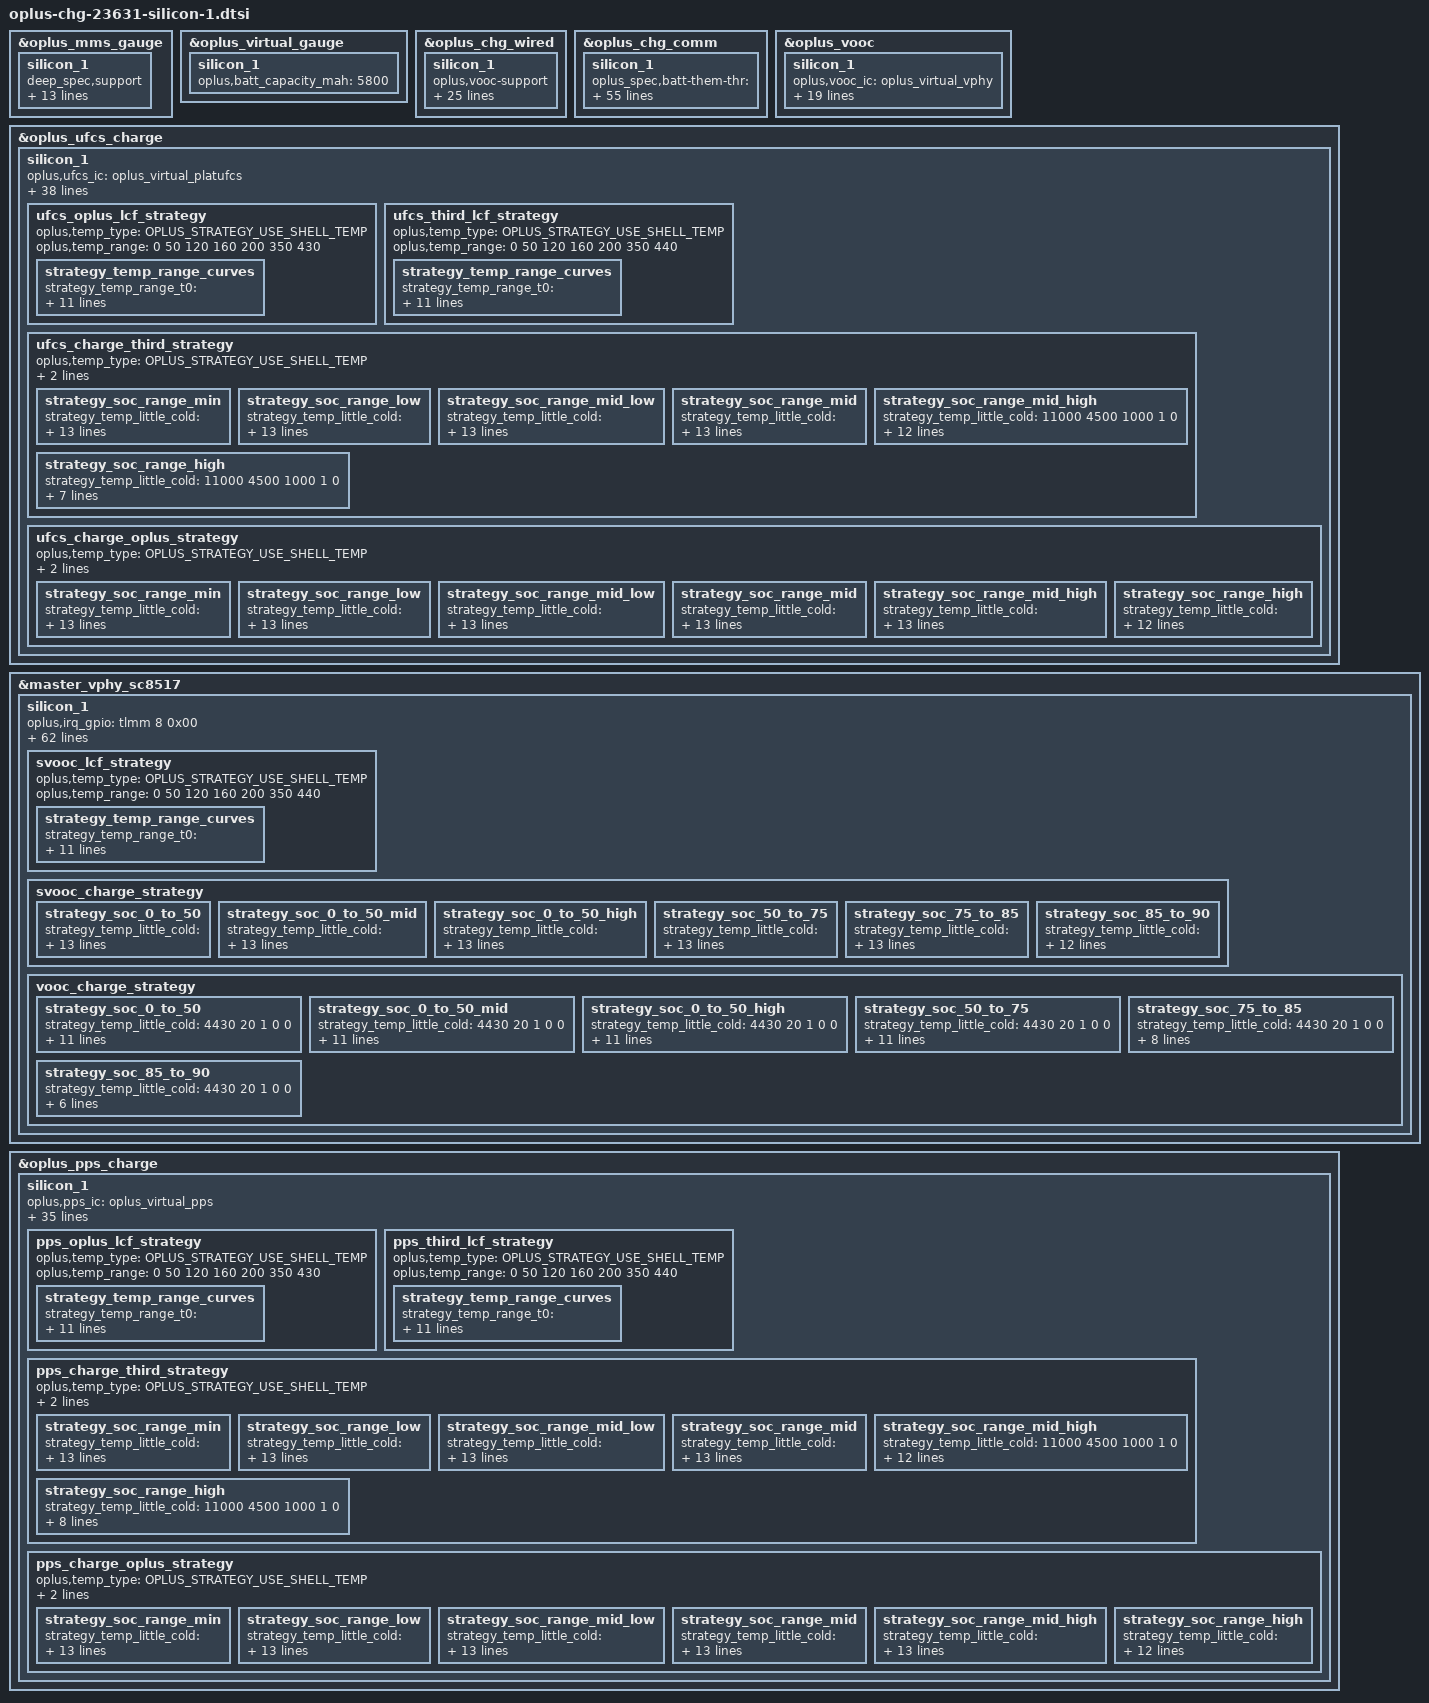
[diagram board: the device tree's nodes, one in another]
//ifdef OPLUS_FEATURE_CHG_BASIC
&oplus_mms_gauge {
	silicon_1 {
		deep_spec,support;
		deep_spec,uv_thr = <3000>;
		deep_spec,count_thr = <50>;
		deep_spec,vbat_soc = <20>;
		deep_spec,count_step = <0 1 0 400 1 1 530 2 2>;
		deep_spec,count_curve = <0 3200 3300 0
					100 3300 3370 1
					200 3350 3400 2
					300 3400 3450 3
					400 3450 3500 4>;
		deep_spec,cc_curve = 	<0 3200 3300 0
					15 3000 3150 1
					500 3100 3250 2
					1000 3200 3300 3
					1500 3200 3300 4>;
		deep_spec,batt_curve = <500 3500 5
					10000 3400 2>;
		deep_spec,cold_uv_offset = <3000 0 0
					    3100 (-100) 1
					    3200 (-200) 2
					    3300 (-300) 3
					    3350 (-300) 4
					    3400 (-300) 5
					    3450 (-300) 6>;
		deep_spec,term_coeff = <3150 238 3
					3250 380 4
					3300 428 5
					3370 570 7
					3400 665 8
					3450 665 8
					3500 665 8>;
	};
};
&oplus_virtual_gauge {
	silicon_1 {
		oplus,batt_capacity_mah = <5800>;
	};
};

&oplus_chg_wired {
	silicon_1 {
		oplus,vooc-support;

		oplus_spec,vbatt_pdqc_to_9v_thr = <5000>;
		oplus_spec,pd-iclmax-ma = <1600>;
		oplus_spec,qc-iclmax-ma = <1600>;
		oplus_spec,non-standard-ibatmax-ma = <1000>;
		oplus_spec,input-power-mw = <
			2500		/* OPLUS_WIRED_CHG_MODE_UNKNOWN */
			2500		/* OPLUS_WIRED_CHG_MODE_SDP */
			7500		/* OPLUS_WIRED_CHG_MODE_CDP */
			10000		/* OPLUS_WIRED_CHG_MODE_DCP */
			15000		/* OPLUS_WIRED_CHG_MODE_VOOC */
			14400		/* OPLUS_WIRED_CHG_MODE_QC */
			14400		/* OPLUS_WIRED_CHG_MODE_PD */
		>;
		oplus_spec,led_on-fccmax-ma = <0 1523 2538 3520 3520 3520 3520 1000 0>;
		oplus_spec,fccmax-ma-lv = <
			0 1410 2200 2200 2200 2200 2200 2200 0	/* OPLUS_WIRED_CHG_MODE_UNKNOWN */
			0 600  600  600  600  600  600  600  0	/* OPLUS_WIRED_CHG_MODE_SDP */
			0 1523 1600 1600 1600 1600 1600 1600 0	/* OPLUS_WIRED_CHG_MODE_CDP */
			0 1523 2200 2200 2200 2200 2200 2200 0	/* OPLUS_WIRED_CHG_MODE_DCP */
			0 1523 2538 3300 3300 3300 3300 3046 0	/* OPLUS_WIRED_CHG_MODE_VOOC */
			0 1523 2538 3520 3520 3520 3520 3046 0	/* OPLUS_WIRED_CHG_MODE_QC */
			0 1523 2538 3520 3520 3520 3520 3046 0	/* OPLUS_WIRED_CHG_MODE_PD */
		>;
		oplus_spec,fccmax-ma-hv = <
			0 508  846  2200 2200 2200 2200 2200 0	/* OPLUS_WIRED_CHG_MODE_UNKNOWN */
			0 508  600  600  600  600  600  600  0	/* OPLUS_WIRED_CHG_MODE_SDP */
			0 508  1015 1600 1600 1600 1600 1600 0	/* OPLUS_WIRED_CHG_MODE_CDP */
			0 508  1015 2200 2200 2200 2200 2200 0	/* OPLUS_WIRED_CHG_MODE_DCP */
			0 508  1015 2538 2538 3600 3600 3046 0	/* OPLUS_WIRED_CHG_MODE_VOOC */
			0 508  1015 2538 3520 3520 3520 3046 0	/* OPLUS_WIRED_CHG_MODE_QC */
			0 508  1015 2538 3520 3520 3520 3046 0	/* OPLUS_WIRED_CHG_MODE_PD */
		>;

		oplus_spec,cool_down_pdqc_vol_mv = <9000 9000 9000>;
		oplus_spec,cool_down_pdqc_curr_ma = <1200 1500 1600>;
		oplus_spec,cool_down_vooc_curr_ma = <1200 1500 2000 2500 3000 3000>;
		oplus_spec,cool_down_normal_curr_ma = <1200 1500 2000>;

		oplus_spec,vbus_ov_thr_mv = <11000 11000>;
		oplus_spec,vbus_uv_thr_mv = <4300 4300>;

		/* first data is strategy used temp type */
		oplus,vooc_strategy_name = "cgcl";
		oplus,vooc_strategy_data = <OPLUS_STRATEGY_USE_BATT_TEMP
					    0   350 3000 1 0
					    330 370 3000 2 0
					    350 440 2200 2 1>;
	};
};

&oplus_chg_comm {
	silicon_1 {
		oplus_spec,batt-them-thr = <(-100) 0 50 120 160 350 450 530>;
		oplus_spec,iterm-ma = <151>;
		oplus_spec,fv-mv = <4500 4500 4500 4500 4500 4500 4485 4130 4130>;
		oplus_spec,sw-fv-mv = <4450 4450 4450 4450 4450 4450 4435 4080 4080>;
		oplus_spec,hw-fv-inc-mv = <0 18 18 18 18 18 18 18 0>;
		oplus_spec,sw-over-fv-mv = <4510 4510 4510 4510 4510 4510 4495 4140 4140>;
		oplus_spec,sw-over-fv-dec-mv = <8>;
		oplus_spec,non-standard-sw-fv-mv = <3930>;
		oplus_spec,non-standard-fv-mv = <3980>;
		oplus_spec,non-standard-hw-fv-inc-mv = <18>;
		oplus_spec,non-standard-sw-over-fv-mv = <3990>;
		oplus_spec,non-standard-vbatdet-mv = <3680>;
		oplus_spec,wired-vbatdet-mv = <0 4200 4300 4400 4400 4400 4385 4030 0>;
		oplus_spec,fcc-gear-thr-mv = <4180>;
		oplus_spec,fcc-gear-shake-mv = <400 400 400 300 300 180 180 180 180>;
		oplus_spec,vbatt-ov-thr-mv = <4600>;

		oplus_spec,full_pre_ffc_judge;
		oplus_spec,full-pre-ffc-mv = <4495>;
		oplus_spec,ffc-temp-thr = <120 200 350 400>;
		oplus_spec,wired-ffc-step-max = <2>;
		oplus_spec,wired-ffc-fv-mv = <4590 4590>;

		oplus_spec,wired-ffc-fv-cutoff-mv = <4545 4515 4500
						     4515 4505 4490>;

		oplus_spec,removed_bat_decidegc = <390>;

		oplus_spec,wired-ffc-fcc-ma = <1100 1100 1100
					       700 700  700>;
		oplus_spec,wired-ffc-fcc-cutoff-ma = <400 400 400
						      200 200 200>;

		/* 2s battery */
		oplus_spec,wired-aging-ffc-version = <AGING_FFC_V1>;
		oplus_spec,wired-aging-ffc-offset-mv = <15 30
							10 20>;
		oplus_spec,wired-aging-ffc-cycle-thr = <500 1000>;

		oplus_spec,vbat_uv_thr_mv = <3000>;
		oplus_spec,vbat_charging_uv_thr_mv = <2900>;

		/*If use subboard NTC as battery temp, config it as 20, otherwise 0 */
		oplus_spec,tbatt_power_off_cali_temp = <0>;
		oplus_spec,poweroff_high_batt_temp = <720>;
		oplus_spec,poweroff_emergency_batt_temp = <770>;
		oplus,vooc_show_ui_soc_decimal;
		oplus,ui_soc_decimal_speedmin = <20>;

		deep_spec,uv_inc_tbatt = <(-50)>;

		oplus,ui_soc_2_voltage_comp_mv = <30>;
		oplus,chg_shutdown_max_mv = <3000>;

		oplus,gauge_stuck_jump_support;
		oplus,gauge_stuck_threshold = <15>;
		oplus,gauge_stuck_time = <50>;

		oplus,hidden_soc_switch;
		oplus,reserve_chg_soc = <3>;
		oplus,hidden_soc_percent = <20>;
	};
};

&oplus_vooc {
	silicon_1 {
		oplus,vooc_ic = <&oplus_virtual_vphy>;

		oplus_spec,vooc_soc_range = <50 75 85>;

		oplus,vooc_data_width = <7>;
		oplus,vooc_curr_max = <CURR_LIMIT_7BIT_11_5A>;
		oplus,support_vooc_by_normal_charger_path;
		oplus,vooc_project = <14>;  /* 120W, 11V10.9A */
		oplus,vooc_curr_table_type = <VOOC_CURR_TABLE_2_0>;
		oplus,vooc_power_max_w = <120>;
		oplus,voocphy_support = <2>;
		oplus,support_fake_vooc_check;
		oplus,subboard_ntc_abnormal_current = <7300>;
		oplus,smart_chg_bcc_support;
		oplus,abnormal_over_80w_adapter_current = <CURR_LIMIT_7BIT_11_5A CURR_LIMIT_7BIT_11_5A
						CURR_LIMIT_7BIT_7_0A CURR_LIMIT_7BIT_7_0A
						CURR_LIMIT_7BIT_6_0A CURR_LIMIT_7BIT_6_0A
						CURR_LIMIT_7BIT_5_0A CURR_LIMIT_7BIT_5_0A
						CURR_LIMIT_7BIT_4_0A CURR_LIMIT_7BIT_4_0A
						CURR_LIMIT_7BIT_3_0A CURR_LIMIT_7BIT_3_0A
						CURR_LIMIT_7BIT_2_0A CURR_LIMIT_7BIT_2_0A>;


		oplus,abnormal_adapter_current = <CURR_LIMIT_7BIT_11_5A CURR_LIMIT_7BIT_11_5A
						CURR_LIMIT_7BIT_5_0A CURR_LIMIT_7BIT_5_0A
						CURR_LIMIT_7BIT_4_0A CURR_LIMIT_7BIT_4_0A
						CURR_LIMIT_7BIT_3_0A CURR_LIMIT_7BIT_3_0A
						CURR_LIMIT_7BIT_2_0A CURR_LIMIT_7BIT_2_0A>;

		/* first data is strategy used temp type */
		oplus,general_strategy_name = "cgcl";
		oplus,general_strategy_data = < OPLUS_STRATEGY_USE_SHELL_TEMP
						0   380 CURR_LIMIT_7BIT_11_5A 1 0
						370 400 CURR_LIMIT_7BIT_8_0A 2 0
						390 420 CURR_LIMIT_7BIT_7_0A 3 1
						410 430 CURR_LIMIT_7BIT_4_0A 4 2
						420 440 CURR_LIMIT_7BIT_3_0A 4 3 >;
	};
};

&oplus_ufcs_charge {
	silicon_1 {
		oplus,ufcs_ic = <&oplus_virtual_platufcs>;
		oplus,cp_ic = <&oplus_ufcs_virtual_cp>;
		oplus,dpdm_switch_ic = <&oplus_adsp_dpdm_switch>;

		oplus,adsp_ufcs_project;
		oplus,impedance_unit = <&oplus_ufcs_impedance_unit>;

		oplus,target_vbus_mv = <11000>;
		oplus,curr_max_ma = <3000>;

		oplus,ufcs_warm_allow_vol = <4000>;
		oplus,ufcs_warm_allow_soc = <55>;
		oplus,ufcs_strategy_normal_current = <3000>;
		oplus,ufcs_over_high_or_low_current = <3000>;
		oplus,ufcs_timeout_third = <14502>;
		oplus,ufcs_timeout_oplus = <14502>;
		oplus,ufcs_ibat_over_third = <4400>;
		oplus,ufcs_ibat_over_oplus = <4400>;
		oplus,ufcs_full_cool_sw_vbat = <4570>;
		oplus,ufcs_full_normal_sw_vbat = <4575>;
		oplus,ufcs_full_normal_hw_vbat = <4585>;
		oplus,ufcs_full_ffc_vbat = <4495>;
		oplus,ufcs_full_warm_vbat = <4130>;
		oplus,ufcs_full_cool_sw_vbat_third = <4500>;
		oplus,ufcs_full_normal_sw_vbat_third= <4500>;
		oplus,ufcs_full_normal_hw_vbat_third = <4510>;
		oplus,ufcs_current_change_timeout = <100>;
		oplus,ufcs_r_default = <90 60 60 60 60 60 60>;
		oplus,ufcs_rmos_mohm = <5>;
		oplus,ufcs_r_limit = <260 200 140 90 40>;
		oplus,ufcs_strategy_batt_high_temp = <410 420 435 400 410 425>;
		oplus,ufcs_strategy_high_current = <3000 3000 2000 3000 3000 3000>;
		oplus,ufcs_little_cool_high_temp = <200>;
		oplus,curve_strategy_name = "pps_ufcs_curve_v2";
		oplus_spec,ufcs_high_soc = <95>;
		oplus,ufcs_charge_strategy_soc = <0 20 35 55 75 85 95>;
		oplus,ufcs_charge_strategy_temp = <0 50 120 160 350 440 510>;

		ufcs_oplus_lcf_strategy {
			oplus,temp_type = <OPLUS_STRATEGY_USE_SHELL_TEMP>;
			oplus,temp_range = <0 50 120 160 200 350 430>;

			strategy_temp_range_curves {
				strategy_temp_range_t0 =	<370 4570 0
								 320 4560 0
								 270 4550 0
								 220 4540 0
								 170 4530 1>;
				strategy_temp_range_t1 =	<500 4570 0
								 450 4560 0
								 400 4550 0
								 350 4540 0
								 300 4530 1>;
				strategy_temp_range_t2 =	<600 4570 0
								 500 4565 0
								 400 4550 0
								 300 4540 0
								 200 4530 1>;
				strategy_temp_range_t3 =	<600 4570 0
								 500 4565 0
								 400 4550 0
								 300 4540 0
								 200 4530 1>;
				strategy_temp_range_t4 =	<1700 4570 0
								 1600 4565 0
								 1500 4550 0
								 1400 4540 0
								 1300 4530 1>;
				strategy_temp_range_t5 =	<1900 4570 0
								 1800 4565 0
								 1700 4550 0
								 1600 4540 0
								 1500 4530 1>;
			};
		};

		ufcs_third_lcf_strategy {
			oplus,temp_type = <OPLUS_STRATEGY_USE_SHELL_TEMP>;
			oplus,temp_range = <0 50 120 160 200 350 440>;

			strategy_temp_range_curves {
				strategy_temp_range_t0 =	<950 4500 0
								 850 4490 0
								 750 4480 0
								 650 4470 0
								 550 4460 1>;
				strategy_temp_range_t1 =	<950 4500 0
								 850 4490 0
								 750 4480 0
								 650 4470 0
								 550 4460 1>;
				strategy_temp_range_t2 =	<950 4500 0
								 850 4495 0
								 750 4480 0
								 650 4470 0
								 550 4460 1>;
				strategy_temp_range_t3 =	<950 4500 0
								 850 4495 0
								 750 4480 0
								 650 4470 0
								 550 4460 1>;
				strategy_temp_range_t4 =	<950 4500 0
								 850 4495 0
								 750 4480 0
								 650 4470 0
								 550 4460 1>;
				strategy_temp_range_t5 =	<950 4485 0
								 850 4480 0
								 750 4465 0
								 650 4455 0
								 550 4445 1>;
			};
		};

		ufcs_charge_third_strategy {
			oplus,temp_type = <OPLUS_STRATEGY_USE_SHELL_TEMP>;
			oplus,soc_range = <0 20 35 55 75 85 95>;
			oplus,temp_range = <0 50 120 160 200 350 440 510>;

			strategy_soc_range_min {
				strategy_temp_little_cold =	<11000 4150 1200 0 0
								11000 4500 1000 1 0>;
				strategy_temp_cool =		<11000 4150 2100 0 0
								 11000 4150 2000 0 0
								11000 4150 1500 0 0
								11000 4490 1200 0 0
								11000 4500 1000 1 0>;
				strategy_temp_little_cool =	<11000 4150 2700 0 0
								11000 4150 2500 0 0
								11000 4330 2100 0 0
								11000 4330 2000 0 0
								11000 4330 1500 0 0
								11000 4490 1200 0 0
								11000 4500 1000 1 0>;
				strategy_temp_little_cool_high =	<11000 4490 3000 0 0
								11000 4490 2700 0 0
								11000 4490 2500 0 0
								11000 4490 2000 0 0
								11000 4490 1500 0 0
								11000 4500 1000 1 0>;
				strategy_temp_normal_low =	<11000 4490 3000 0 0
								11000 4490 2500 0 0
								11000 4490 2000 0 0
								11000 4490 1500 0 0
								11000 4500 1000 1 0>;
				strategy_temp_normal_high =	<11000 4475 3000 0 0
								11000 4475 2500 0 0
								11000 4475 2000 0 0
								11000 4475 1500 0 0
								11000 4485 1000 1 0>;
				strategy_temp_warm =		<11000 4120 1500 0 0
								11000 4130 1000 1 0>;
			};
			strategy_soc_range_low {
				strategy_temp_little_cold =	<11000 4150 1200 0 0
								11000 4500 1000 1 0>;
				strategy_temp_cool =		<11000 4150 2100 0 0
								11000 4150 2000 0 0
								11000 4150 1500 0 0
								11000 4490 1200 0 0
								11000 4500 1000 1 0>;
				strategy_temp_little_cool =	<11000 4150 2700 0 0
								11000 4150 2500 0 0
								11000 4330 2100 0 0
								11000 4330 2000 0 0
								11000 4330 1500 0 0
								11000 4490 1200 0 0
								11000 4500 1000 1 0>;
				strategy_temp_little_cool_high =	<11000 4490 3000 0 0
								11000 4490 2700 0 0
								11000 4490 2500 0 0
								11000 4490 2000 0 0
								11000 4490 1500 0 0
								11000 4500 1000 1 0>;
				strategy_temp_normal_low =	<11000 4490 3000 0 0
								11000 4490 2500 0 0
								11000 4490 2000 0 0
								11000 4490 1500 0 0
								11000 4500 1000 1 0>;
				strategy_temp_normal_high =	<11000 4475 3000 0 0
								11000 4475 2500 0 0
								11000 4475 2000 0 0
								11000 4475 1500 0 0
								11000 4485 1000 1 0>;
				strategy_temp_warm =		<11000 4120 1500 0 0
								11000 4130 1000 1 0>;
			};
			strategy_soc_range_mid_low {
				strategy_temp_little_cold =	<11000 4150 1200 0 0
								11000 4500 1000 1 0>;
				strategy_temp_cool =		<11000 4150 2100 0 0
								11000 4150 2000 0 0
								11000 4150 1500 0 0
								11000 4490 1200 0 0
								11000 4500 1000 1 0>;
				strategy_temp_little_cool =	<11000 4150 2700 0 0
								11000 4150 2500 0 0
								11000 4330 2100 0 0
								11000 4330 2000 0 0
								11000 4330 1500 0 0
								11000 4490 1200 0 0
								11000 4500 1000 1 0>;
				strategy_temp_little_cool_high =	<11000 4490 3000 0 0
								11000 4490 2700 0 0
								11000 4490 2500 0 0
								11000 4490 2000 0 0
								11000 4490 1500 0 0
								11000 4500 1000 1 0>;
				strategy_temp_normal_low =	<11000 4490 3000 0 0
								11000 4490 2500 0 0
								11000 4490 2000 0 0
								11000 4490 1500 0 0
								11000 4500 1000 1 0>;
				strategy_temp_normal_high =	<11000 4475 3000 0 0
								11000 4475 2500 0 0
								11000 4475 2000 0 0
								11000 4475 1500 0 0
								11000 4485 1000 1 0>;
				strategy_temp_warm =		<11000 4120 1500 0 0
								11000 4130 1000 1 0>;

			};
			strategy_soc_range_mid {
				strategy_temp_little_cold =	<11000 4150 1200 0 0
								11000 4500 1000 1 0>;
				strategy_temp_cool =		<11000 4150 2000 0 0
								11000 4150 1500 0 0
								11000 4490 1200 0 0
								11000 4500 1000 1 0>;
				strategy_temp_little_cool =	<11000 4150 2700 0 0
								11000 4150 2500 0 0
								11000 4330 2100 0 0
								11000 4330 2000 0 0
								11000 4330 1500 0 0
								11000 4490 1200 0 0
								11000 4500 1000 1 0>;
				strategy_temp_little_cool_high =	<11000 4490 3000 0 0
								11000 4490 2700 0 0
								11000 4490 2500 0 0
								11000 4490 2000 0 0
								11000 4490 1500 0 0
								11000 4500 1000 1 0>;
				strategy_temp_normal_low =	<11000 4490 3000 0 0
								11000 4490 2500 0 0
								11000 4490 2000 0 0
								11000 4490 1500 0 0
								11000 4500 1000 1 0>;
				strategy_temp_normal_high =	<11000 4475 3000 0 0
								11000 4475 2500 0 0
								11000 4475 2000 0 0
								11000 4475 1500 0 0
								11000 4485 1000 1 0>;
				strategy_temp_warm =		<11000 4120 1500 0 0
								11000 4130 1000 1 0>;
			};
			strategy_soc_range_mid_high {
				strategy_temp_little_cold =	<11000 4500 1000 1 0>;
				strategy_temp_cool =		<11000 4150 1500 0 0
								11000 4490 1200 0 0
								11000 4500 1000 1 0>;
				strategy_temp_little_cool =	<11000 4330 2000 0 0
								11000 4330 1500 0 0
								11000 4490 1200 0 0
								11000 4500 1000 1 0>;
				strategy_temp_little_cool_high =	<11000 4490 2000 0 0
								11000 4490 1500 0 0
								11000 4500 1000 1 0>;
				strategy_temp_normal_low =	<11000 4490 2500 0 0
								11000 4490 2000 0 0
								11000 4490 1500 0 0
								11000 4500 1000 1 0>;
				strategy_temp_normal_high =	<11000 4475 2500 0 0
								11000 4475 2000 0 0
								11000 4475 1500 0 0
								11000 4485 1000 1 0>;
				strategy_temp_warm =		<11000 4120 1500 0 0
								11000 4130 1000 1 0>;
			};
			strategy_soc_range_high {
				strategy_temp_little_cold =	<11000 4500 1000 1 0>;
				strategy_temp_cool =		<11000 4500 1000 1 0>;
				strategy_temp_little_cool =	<11000 4500 1000 1 0>;
				strategy_temp_little_cool_high =	<11000 4500 1000 1 0>;
				strategy_temp_normal_low =	<11000 4500 1000 1 0>;
				strategy_temp_normal_high =	<11000 4485 1000 1 0>;
				strategy_temp_warm =		<11000 4130 1000 1 0>;
			};
		};

		ufcs_charge_oplus_strategy {
			oplus,temp_type = <OPLUS_STRATEGY_USE_SHELL_TEMP>;
			oplus,soc_range = <0 20 35 55 75 85 95>;
			oplus,temp_range = <0 50 120 160 200 350 440 510>;

			strategy_soc_range_min {
				strategy_temp_little_cold =	<11000 4150 1200 0 0
								11000 4150 1000 0 0
								11000 4570 700 1 0>;
				strategy_temp_cool =		<11000 4150 2100 0 0
								 11000 4150 2000 0 0
								11000 4150 1500 0 0
								11000 4510 1200 0 0
								11000 4510 1000 0 0
								11000 4570 700 1 0>;
				strategy_temp_little_cool =	<11000 4150 2700 0 0
								11000 4150 2500 0 0
								11000 4330 2100 0 0
								11000 4330 2000 0 0
								11000 4330 1500 0 0
								11000 4560 1200 0 0
								11000 4560 1000 0 0
								11000 4570 700 1 0>;
				strategy_temp_little_cool_high =	<11000 4150 2700 0 0
								11000 4150 2500 0 0
								11000 4330 2100 0 0
								11000 4330 2000 0 0
								11000 4330 1500 0 0
								11000 4560 1200 0 0
								11000 4560 1000 0 0
								11000 4570 700 1 0>;
				strategy_temp_normal_low =	<11000 4560 3000 0 0
								11000 4560 2500 0 0
								11000 4560 2000 0 0
								11000 4570 1800 1 0>;
				strategy_temp_normal_high =	<11000 4560 3000 0 0
								11000 4560 2500 0 0
								11000 4570 2000 1 0>;
				strategy_temp_warm =		<11000 4120 1500 0 0
								11000 4120 1000 0 0
								11000 4130 700 1 0>;
			};
			strategy_soc_range_low {
				strategy_temp_little_cold =	<11000 4150 1200 0 0
								11000 4150 1000 0 0
								11000 4570 700 1 0>;
				strategy_temp_cool =		<11000 4150 2100 0 0
								 11000 4150 2000 0 0
								11000 4150 1500 0 0
								11000 4510 1200 0 0
								11000 4510 1000 0 0
								11000 4570 700 1 0>;
				strategy_temp_little_cool =	<11000 4150 2700 0 0
								11000 4150 2500 0 0
								11000 4330 2100 0 0
								11000 4330 2000 0 0
								11000 4330 1500 0 0
								11000 4560 1200 0 0
								11000 4560 1000 0 0
								11000 4570 700 1 0>;
				strategy_temp_little_cool_high =	<11000 4150 2700 0 0
								11000 4150 2500 0 0
								11000 4330 2100 0 0
								11000 4330 2000 0 0
								11000 4330 1500 0 0
								11000 4560 1200 0 0
								11000 4560 1000 0 0
								11000 4570 700 1 0>;
				strategy_temp_normal_low =	<11000 4560 3000 0 0
								11000 4560 2500 0 0
								11000 4560 2000 0 0
								11000 4570 1800 1 0>;
				strategy_temp_normal_high =	<11000 4560 3000 0 0
								11000 4560 2500 0 0
								11000 4570 2000 1 0>;
				strategy_temp_warm =		<11000 4120 1500 0 0
								11000 4120 1000 0 0
								11000 4130 700 1 0>;
			};
			strategy_soc_range_mid_low {
				strategy_temp_little_cold =	<11000 4150 1000 0 0
								11000 4570 700 1 0>;
				strategy_temp_cool =		<11000 4150 2000 0 0
								11000 4150 1500 0 0
								11000 4510 1200 0 0
								11000 4510 1000 0 0
								11000 4570 700 1 0>;
				strategy_temp_little_cool =	<11000 4150 2700 0 0
								11000 4150 2500 0 0
								11000 4330 2100 0 0
								11000 4330 2000 0 0
								11000 4330 1500 0 0
								11000 4560 1200 0 0
								11000 4560 1000 0 0
								11000 4570 700 1 0>;
				strategy_temp_little_cool_high =	<11000 4150 2700 0 0
								11000 4150 2500 0 0
								11000 4330 2100 0 0
								11000 4330 2000 0 0
								11000 4330 1500 0 0
								11000 4560 1200 0 0
								11000 4560 1000 0 0
								11000 4570 700 1 0>;
				strategy_temp_normal_low =	<11000 4560 3000 0 0
								11000 4560 2500 0 0
								11000 4560 2000 0 0
								11000 4570 1800 1 0>;
				strategy_temp_normal_high =	<11000 4560 3000 0 0
								11000 4560 2500 0 0
								11000 4570 2000 1 0>;
				strategy_temp_warm =		<11000 4120 1500 0 0
								11000 4120 1000 0 0
								11000 4130 700 1 0>;
			};
			strategy_soc_range_mid {
				strategy_temp_little_cold =	<11000 4150 1000 0 0
								11000 4570 700 1 0>;
				strategy_temp_cool =		<11000 4150 2000 0 0
								11000 4150 1500 0 0
								11000 4510 1200 0 0
								11000 4510 1000 0 0
								11000 4570 700 1 0>;
				strategy_temp_little_cool =	<11000 4150 2700 0 0
								11000 4150 2500 0 0
								11000 4330 2100 0 0
								11000 4330 2000 0 0
								11000 4330 1500 0 0
								11000 4560 1200 0 0
								11000 4560 1000 0 0
								11000 4570 700 1 0>;
				strategy_temp_little_cool_high =	<11000 4150 2700 0 0
								11000 4150 2500 0 0
								11000 4330 2100 0 0
								11000 4330 2000 0 0
								11000 4330 1500 0 0
								11000 4560 1200 0 0
								11000 4560 1000 0 0
								11000 4570 700 1 0>;
				strategy_temp_normal_low =	<11000 4560 3000 0 0
								11000 4560 2500 0 0
								11000 4560 2000 0 0
								11000 4570 1800 1 0>;
				strategy_temp_normal_high =	<11000 4560 3000 0 0
								11000 4560 2500 0 0
								11000 4570 2000 1 0>;
				strategy_temp_warm =		<11000 4120 1500 0 0
								11000 4120 1000 0 0
								11000 4130 700 1 0>;
			};
			strategy_soc_range_mid_high {
				strategy_temp_little_cold =	<11000 4150 1000 0 0
								11000 4570 700 1 0>;
				strategy_temp_cool =		<11000 4150 2000 0 0
								11000 4150 1500 0 0
								11000 4510 1200 0 0
								11000 4510 1000 0 0
								11000 4570 700 1 0>;
				strategy_temp_little_cool =	<11000 4150 2700 0 0
								11000 4150 2500 0 0
								11000 4330 2100 0 0
								11000 4330 2000 0 0
								11000 4330 1500 0 0
								11000 4560 1200 0 0
								11000 4560 1000 0 0
								11000 4570 700 1 0>;
				strategy_temp_little_cool_high =	<11000 4150 2700 0 0
								11000 4150 2500 0 0
								11000 4330 2100 0 0
								11000 4330 2000 0 0
								11000 4330 1500 0 0
								11000 4560 1200 0 0
								11000 4560 1000 0 0
								11000 4570 700 1 0>;
				strategy_temp_normal_low =	<11000 4560 3000 0 0
								11000 4560 2500 0 0
								11000 4560 2000 0 0
								11000 4570 1800 1 0>;
				strategy_temp_normal_high =	<11000 4560 3000 0 0
								11000 4560 2500 0 0
								11000 4570 2000 1 0>;
				strategy_temp_warm =		<11000 4120 1500 0 0
								11000 4120 1000 0 0
								11000 4130 700 1 0>;
			};
			strategy_soc_range_high {
				strategy_temp_little_cold =	<11000 4150 1000 0 0
								11000 4570 700 1 0>;
				strategy_temp_cool =		<11000 4150 1500 0 0
								11000 4510 1200 0 0
								11000 4510 1000 0 0
								11000 4570 700 1 0>;
				strategy_temp_little_cool =	<11000 4330 1500 0 0
								11000 4560 1200 0 0
								11000 4560 1000 0 0
								11000 4570 700 1 0>;
				strategy_temp_little_cool_high =	<11000 4330 1500 0 0
								11000 4560 1200 0 0
								11000 4560 1000 0 0
								11000 4570 700 1 0>;
				strategy_temp_normal_low =	<11000 4560 2000 0 0
								11000 4570 1800 1 0>;
				strategy_temp_normal_high =	<11000 4570 2000 1 0>;
				strategy_temp_warm =		<11000 4120 1500 0 0
								11000 4120 1000 0 0
								11000 4130 700 1 0>;
			};

		};
	};
};

&master_vphy_sc8517 {
	silicon_1 {
		oplus,irq_gpio = <&tlmm 8 0x00>;

		pinctrl-names = "charging_inter_active", "charging_inter_sleep";
		pinctrl-0 = <&charging_inter_active>;
		pinctrl-1 = <&charging_inter_sleep>;

		oplus,ic_type = <OPLUS_CHG_IC_VPHY>;
		oplus,ic_index = <0>;
		oplus,vooc-version = <VOOC_VERSION_5_0>;

		oplus_spec,external_gauge_support;
		oplus_spec,voocphy_bidirect_cp_support;
		oplus_spec,voocphy_current_default = <109>;

		oplus_spec,svooc_cool_down_current_limit = <109 15 15 20 25 30 35 40 45 50 55 60 63 65 70 75 80 85 109>;
		oplus_spec,vooc_cool_down_current_limit = <60 20 20 20 30 40 50 60>;

		oplus_spec,vooc_little_cold_full_voltage = <4570>;
		oplus_spec,vooc_cool_full_voltage = <4570>;
		oplus_spec,vooc_little_cool_full_voltage = <4570>;
		oplus_spec,vooc_little_cool_high_full_voltage = <4570>;
		oplus_spec,vooc_warm_full_voltage = <4130>;
		oplus_spec,vooc_1time_full_voltage = <4580>;
		oplus_spec,vooc_ntime_full_voltage = <4570>;

		oplus_spec,vooc_multistep_initial_batt_temp = <1000>;
		oplus_spec,vooc_little_cool_temp = <160>;
		oplus_spec,vooc_little_cool_high_temp = <200>;
		oplus_spec,vooc_cool_temp = <120>;
		oplus_spec,vooc_little_cold_temp = <50>;
		oplus_spec,vooc_normal_low_temp = <350>;
		oplus_spec,vooc_strategy_normal_current = <100>;
		oplus_spec,vooc_normal_to_little_cool_current = <100>;
		oplus_spec,vooc_over_high_temp = <510>;
		oplus_spec,vooc_low_temp = <0>;
		oplus_spec,vooc_high_temp = <500>;
		oplus_spec,vooc_low_soc = <0>;
		oplus_spec,vooc_high_soc = <95>;
		oplus_spec,vooc_normal_high_temp = <440>;
		oplus_spec,vooc_warm_vol_thr = <4000>;
		oplus_spec,vooc_warm_soc_thr = <55>;
		oplus_spec,impedance_calculation_newmethod;
		oplus_spec,svooc_circuit_r_l = <0x18>;
		oplus_spec,svooc_circuit_r_h = <0x2>;/* 65 mR */

		oplus_spec,fastchg_timeout_time_init = <145020>;
		oplus_spec,voocphy_ibat_over_current = <12300>;
		oplus_spec,voocphy_cp_max_ibus = <12300>;
		oplus_spec,voocphy_svooc_cp_max_ibus = <3500>;
		oplus_spec,voocphy_vooc_cp_max_ibus = <3500>;
		oplus_spec,batt_pwd_curr_thd1 = <3800>;
		oplus_spec,batt_pwd_vol_thd1 = <4605>;

		oplus_spec,voocphy_req_freq = <1920000 2956800 2956800 3302400>;
		oplus_spec,voocphy_freq_mincore = <1920000>;
		oplus_spec,voocphy_freq_midcore = <2956800>;
		oplus_spec,voocphy_freq_maxcore = <2956800>;
		oplus_spec,voocphy_current_change_timeout = <100>;
		oplus_spec,copycat_vooc_support;
		oplus,abnormal_adapter_current = <CURR_LIMIT_7BIT_11_5A CURR_LIMIT_7BIT_11_5A
						  CURR_LIMIT_7BIT_5_0A CURR_LIMIT_7BIT_5_0A
						  CURR_LIMIT_7BIT_4_0A CURR_LIMIT_7BIT_4_0A
						  CURR_LIMIT_7BIT_3_0A CURR_LIMIT_7BIT_3_0A
						  CURR_LIMIT_7BIT_2_0A CURR_LIMIT_7BIT_2_0A>;

		oplus_spec,soc_range = <0 20 35 55 75 85 95>;

		svooc_batt_sys_curve = <1 0 1 1 0 1 1	// 9100mA
					1 0 1 1 1 0 0	// 4324mV
					0 0 1 0 1 0 0	// 2000mA
					1 1 1 0 1 1 1	// 4594mV
					0 0 0 1 1 0 0	// 1200mA
					1 1 1 0 1 1 1>; // 4594mV

		vooc_batt_sys_curve =  <0 1 0 1 1 0 1 	// 4500mA
					0 0 0 0 0 0 1	// 3414mV
					0 0 1 0 1 0 0	// 2000mA
					1 1 1 0 1 1 1	// 4594mV
					0 0 0 1 0 1 0	// 1000mA
					1 1 1 0 1 1 1>; // 4594mV

		svooc_lcf_strategy {
			oplus,temp_type = <OPLUS_STRATEGY_USE_SHELL_TEMP>;
			oplus,temp_range = <0 50 120 160 200 350 440>;

			strategy_temp_range_curves {
				strategy_temp_range_t0 =	<370 4570 0
								 320 4565 0
								 270 4550 0
								 220 4540 0
								 170 4530 1>;
				strategy_temp_range_t1 =	<500 4570 0
								 450 4565 0
								 400 4550 0
								 350 4540 0
								 300 4530 1>;
				strategy_temp_range_t2 =	<600 4570 0
								 500 4565 0
								 400 4550 0
								 300 4540 0
								 200 4530 1>;
				strategy_temp_range_t3 =	<1000 4570 0
								 950 4565 0
								 850 4550 0
								 750 4540 0
								 600 4530 1>;
				strategy_temp_range_t4 =	<1350 4570 0
								 1300 4565 0
								 1200 4550 0
								 1100 4540 0
								 950  4530 1>;
				strategy_temp_range_t5 =	<2050 4570 0
								 2000 4565 0
								 1900 4550 0
								 1800 4540 0
								 1650 4530 1>;
			};
		};

		svooc_charge_strategy {
			strategy_soc_0_to_50 { /* 0 ~ 20 */
				strategy_temp_little_cold =	<4150 12 0 0 0
								4150 10 0 0 0
								4570  7 1 0 0>;
				strategy_temp_cool =		<4150 21 0 0 0
								4150 20 0 0 0
								4150 15 0 0 0
								4510 12 0 0 0
								4510 10 0 0 0
								4570  7 1 0 0>;
				strategy_temp_little_cool =	<4150 27 0 0 0
								4150 25 0 0 0
								4330 21 0 0 0
								4330 20 0 0 0
								4330 15 0 0 0
								4560 12 0 0 0
								4560 10 0 0 0
								4570  7 1 0 0>;
				strategy_temp_little_cool_high =	<4150 54 0 1200 0
								4150 50 0 600 0
								4150 45 0 600 0
								4330 40 0 0 0
								4330 35 0 0 0
								4510 32 0 0 0
								4510 30 0 0 0
								4560 27 0 0 0
								4560 25 0 0 0
								4560 20 0 0 0
								4560 15 0 0 0
								4570 11 1 0 0>;
				strategy_temp_normal_low =	<4150 109 0 60 0
								4150 91 0 300 0
								4150 90 0 300 0
								4230 85 0 300 0
								4230 80 0 300 0
								4230 75 0 300 0
								4330 73 0 600 0
								4330 70 0 600 0
								4330 65 0 600 0
								4330 60 0 1200 0
								4330 55 0 1200 0
								4430 54 0 1200 0
								4430 50 0 600 0
								4430 45 0 600 0
								4560 40 0 0 0
								4560 35 0 0 0
								4560 30 0 0 0
								4560 25 0 0 0
								4560 20 0 0 0
								4560 15 0 0 0
								4570 14 1 0 0>;
				strategy_temp_normal_high =	<4150 109 0 60 0
								4150 91 0 300 0
								4150 90 0 300 0
								4230 85 0 300 0
								4230 80 0 300 0
								4230 75 0 300 0
								4330 73 0 600 0
								4330 70 0 600 0
								4330 65 0 600 0
								4330 60 0 1200 0
								4330 55 0 1200 0
								4430 54 0 1200 0
								4430 50 0 600 0
								4430 45 0 600 0
								4560 40 0 0 0
								4560 35 0 0 0
								4560 30 0 0 0
								4560 25 0 0 0
								4570 21 1 0 0>;
				strategy_temp_warm =		<4120 15 0 0 0
								4120 10 0 0 0
								4130  7 1 0 0>;
			};

			strategy_soc_0_to_50_mid { /* 21 ~ 35 */
				strategy_temp_little_cold =	<4150 12 0 0 0
								4150 10 0 0 0
								4570  7 1 0 0>;
				strategy_temp_cool =		<4150 21 0 0 0
								4150 20 0 0 0
								4150 15 0 0 0
								4510 12 0 0 0
								4510 10 0 0 0
								4570  7 1 0 0>;
				strategy_temp_little_cool =	<4150 27 0 0 0
								4150 25 0 0 0
								4330 21 0 0 0
								4330 20 0 0 0
								4330 15 0 0 0
								4560 12 0 0 0
								4560 10 0 0 0
								4570  7 1 0 0>;
				strategy_temp_little_cool_high =	<4150 54 0 1200 0
								4150 50 0 600 0
								4150 45 0 600 0
								4330 40 0 0 0
								4330 35 0 0 0
								4510 32 0 0 0
								4510 30 0 0 0
								4560 27 0 0 0
								4560 25 0 0 0
								4560 20 0 0 0
								4560 15 0 0 0
								4570 11 1 0 0>;
				strategy_temp_normal_low =	<4150 109 0 60 0
								4150 91 0 300 0
								4150 90 0 300 0
								4230 85 0 300 0
								4230 80 0 300 0
								4230 75 0 300 0
								4330 73 0 600 0
								4330 70 0 600 0
								4330 65 0 600 0
								4330 60 0 1200 0
								4330 55 0 1200 0
								4430 54 0 1200 0
								4430 50 0 600 0
								4430 45 0 600 0
								4560 40 0 0 0
								4560 35 0 0 0
								4560 30 0 0 0
								4560 25 0 0 0
								4560 20 0 0 0
								4560 15 0 0 0
								4570 14 1 0 0>;
				strategy_temp_normal_high =	<4150 109 0 60 0
								4150 91 0 300 0
								4150 90 0 300 0
								4230 85 0 300 0
								4230 80 0 300 0
								4230 75 0 300 0
								4330 73 0 600 0
								4330 70 0 600 0
								4330 65 0 600 0
								4330 60 0 1200 0
								4330 55 0 1200 0
								4430 54 0 1200 0
								4430 50 0 600 0
								4430 45 0 600 0
								4560 40 0 0 0
								4560 35 0 0 0
								4560 30 0 0 0
								4560 25 0 0 0
								4570 21 1 0 0>;
				strategy_temp_warm =		<4120 15 0 0 0
								4120 10 0 0 0
								4130  7 1 0 0>;
			};

			strategy_soc_0_to_50_high { /* 36 ~ 55 */
				strategy_temp_little_cold =	<4150 10 0 0 0
								4570  7 1 0 0>;
				strategy_temp_cool =		<4150 20 0 0 0
								4150 15 0 0 0
								4510 12 0 0 0
								4510 10 0 0 0
								4570  7 1 0 0>;
				strategy_temp_little_cool =	<4150 27 0 0 0
								4150 25 0 0 0
								4330 21 0 0 0
								4330 20 0 0 0
								4330 15 0 0 0
								4560 12 0 0 0
								4560 10 0 0 0
								4570  7 1 0 0>;
				strategy_temp_little_cool_high =	<4150 54 0 1200 0
								4150 50 0 600 0
								4150 45 0 600 0
								4330 40 0 0 0
								4330 35 0 0 0
								4510 32 0 0 0
								4510 30 0 0 0
								4560 27 0 0 0
								4560 25 0 0 0
								4560 20 0 0 0
								4560 15 0 0 0
								4570 11 1 0 0>;
				strategy_temp_normal_low =	<4150 109 0 60 0
								4150 91 0 300 0
								4150 90 0 300 0
								4230 85 0 300 0
								4230 80 0 300 0
								4230 75 0 300 0
								4330 73 0 600 0
								4330 70 0 600 0
								4330 65 0 600 0
								4330 60 0 1200 0
								4330 55 0 1200 0
								4430 54 0 1200 0
								4430 50 0 600 0
								4430 45 0 600 0
								4560 40 0 0 0
								4560 35 0 0 0
								4560 30 0 0 0
								4560 25 0 0 0
								4560 20 0 0 0
								4560 15 0 0 0
								4570 14 1 0 0>;
				strategy_temp_normal_high =	<4150 109 0 60 0
								4150 91 0 300 0
								4150 90 0 300 0
								4230 85 0 300 0
								4230 80 0 300 0
								4230 75 0 300 0
								4330 73 0 600 0
								4330 70 0 600 0
								4330 65 0 600 0
								4330 60 0 1200 0
								4330 55 0 1200 0
								4430 54 0 1200 0
								4430 50 0 600 0
								4430 45 0 600 0
								4560 40 0 0 0
								4560 35 0 0 0
								4560 30 0 0 0
								4560 25 0 0 0
								4570 21 1 0 0>;
				strategy_temp_warm =		<4120 15 0 0 0
								4120 10 0 0 0
								4130  7 1 0 0>;
			};

			strategy_soc_50_to_75 { /* 56 ~ 75 */
				strategy_temp_little_cold =	<4150 10 0 0 0
								4570  7 1 0 0>;
				strategy_temp_cool =		<4150 20 0 0 0
								4150 15 0 0 0
								4510 12 0 0 0
								4510 10 0 0 0
								4570  7 1 0 0>;
				strategy_temp_little_cool =	<4150 27 0 0 0
								4150 25 0 0 0
								4330 21 0 0 0
								4330 20 0 0 0
								4330 15 0 0 0
								4560 12 0 0 0
								4560 10 0 0 0
								4570  7 1 0 0>;
				strategy_temp_little_cool_high =	<4330 40 0 0 0
								4330 35 0 0 0
								4510 32 0 0 0
								4510 30 0 0 0
								4560 27 0 0 0
								4560 25 0 0 0
								4560 20 0 0 0
								4560 15 0 0 0
								4570 11 1 0 0>;
				strategy_temp_normal_low =	<4430 45 0 600 0
								4560 40 0 0 0
								4560 35 0 0 0
								4560 30 0 0 0
								4560 25 0 0 0
								4560 20 0 0 0
								4560 15 0 0 0
								4570 14 1 0 0>;
				strategy_temp_normal_high =	<4430 50 0 600 0
								4430 45 0 600 0
								4560 40 0 0 0
								4560 35 0 0 0
								4560 30 0 0 0
								4560 25 0 0 0
								4570 21 1 0 0>;
				strategy_temp_warm =		<4120 15 0 0 0
								4120 10 0 0 0
								4130  7 1 0 0>;
			};

			strategy_soc_75_to_85 { /* 76 ~ 85 */
				strategy_temp_little_cold =	<4150 10 0 0 0
								4570  7 1 0 0>;
				strategy_temp_cool =		<4150 20 0 0 0
								4150 15 0 0 0
								4510 12 0 0 0
								4510 10 0 0 0
								4570  7 1 0 0>;
				strategy_temp_little_cool =	<4150 27 0 0 0
								4150 25 0 0 0
								4330 21 0 0 0
								4330 20 0 0 0
								4330 15 0 0 0
								4560 12 0 0 0
								4560 10 0 0 0
								4570  7 1 0 0>;
				strategy_temp_little_cool_high =	<4510 30 0 0 0
								4560 27 0 0 0
								4560 25 0 0 0
								4560 20 0 0 0
								4560 15 0 0 0
								4570 11 1 0 0>;
				strategy_temp_normal_low =	<4560 35 0 0 0
								4560 30 0 0 0
								4560 25 0 0 0
								4560 20 0 0 0
								4560 15 0 0 0
								4570 14 1 0 0>;
				strategy_temp_normal_high =	<4560 35 0 0 0
								4560 30 0 0 0
								4560 25 0 0 0
								4570 21 1 0 0>;
				strategy_temp_warm =		<4120 15 0 0 0
								4120 10 0 0 0
								4130  7 1 0 0>;
			};

			strategy_soc_85_to_90 { /* 86 ~ 95 */
				strategy_temp_little_cold =	<4150 10 0 0 0
								4570  7 1 0 0>;
				strategy_temp_cool =		<4150 15 0 0 0
								4510 12 0 0 0
								4510 10 0 0 0
								4570  7 1 0 0>;
				strategy_temp_little_cool =	<4330 15 0 0 0
								4560 12 0 0 0
								4560 10 0 0 0
								4570  7 1 0 0>;
				strategy_temp_little_cool_high =	<4560 15 0 0 0
								4570 11 1 0 0>;
				strategy_temp_normal_low =	<4560 20 0 0 0
								4560 15 0 0 0
								4570 14 1 0 0>;
				strategy_temp_normal_high =	<4570 21 1 0 0>;
				strategy_temp_warm =		<4120 15 0 0 0
								4120 10 0 0 0
								4130  7 1 0 0>;
			};
		};

		vooc_charge_strategy {
			strategy_soc_0_to_50 {
				strategy_temp_little_cold =	<4430 20 1 0 0>;
				strategy_temp_cool =		<4420 30 0 0 0
								 4430 20 1 0 0>;
				strategy_temp_little_cool =	<4475 30 0 0 0
								 4480 20 1 0 0>;
				strategy_temp_little_cool_high =	<4475 30 0 0 0
								 4480 20 1 0 0>;
				strategy_temp_normal_low =	<4475 30 0 0 0
								 4480 20 1 0 0>;
				strategy_temp_normal_high =	<4475 30 0 0 0
								 4480 20 1 0 0>;
				strategy_temp_warm =		<4130 24 1 0 0>;
			};

			strategy_soc_0_to_50_mid {
				strategy_temp_little_cold =	<4430 20 1 0 0>;
				strategy_temp_cool =		<4420 30 0 0 0
								 4430 20 1 0 0>;
				strategy_temp_little_cool =	<4475 30 0 0 0
								 4480 20 1 0 0>;
				strategy_temp_little_cool_high =	<4475 30 0 0 0
								 4480 20 1 0 0>;
				strategy_temp_normal_low =	<4475 30 0 0 0
								 4480 20 1 0 0>;
				strategy_temp_normal_high =	<4475 30 0 0 0
								 4480 20 1 0 0>;
				strategy_temp_warm =		<4130 24 1 0 0>;
			};

			strategy_soc_0_to_50_high {
				strategy_temp_little_cold =	<4430 20 1 0 0>;
				strategy_temp_cool =		<4420 30 0 0 0
								 4430 20 1 0 0>;
				strategy_temp_little_cool =	<4475 30 0 0 0
								 4480 20 1 0 0>;
				strategy_temp_little_cool_high =	<4475 30 0 0 0
								 4480 20 1 0 0>;
				strategy_temp_normal_low =	<4475 30 0 0 0
								 4480 20 1 0 0>;
				strategy_temp_normal_high =	<4475 30 0 0 0
								 4480 20 1 0 0>;
				strategy_temp_warm =		<4130 24 1 0 0>;
			};

			strategy_soc_50_to_75 {
				strategy_temp_little_cold =	<4430 20 1 0 0>;
				strategy_temp_cool =		<4420 30 0 0 0
								 4430 20 1 0 0>;
				strategy_temp_little_cool =	<4475 30 0 0 0
								 4480 20 1 0 0>;
				strategy_temp_little_cool_high =	<4475 30 0 0 0
								 4480 20 1 0 0>;
				strategy_temp_normal_low =	<4475 30 0 0 0
								 4480 20 1 0 0>;
				strategy_temp_normal_high =	<4475 30 0 0 0
								 4480 20 1 0 0>;
				strategy_temp_warm =		<4130 24 1 0 0>;
			};

			strategy_soc_75_to_85 {
				strategy_temp_little_cold =	<4430 20 1 0 0>;
				strategy_temp_cool =		<4430 20 1 0 0>;
				strategy_temp_little_cool =	<4480 20 1 0 0>;
				strategy_temp_little_cool_high =	<4480 20 1 0 0>;
				strategy_temp_normal_low =	<4475 30 0 0 0
								 4480 20 1 0 0>;
				strategy_temp_normal_high =	<4475 30 0 0 0
								 4480 20 1 0 0>;
				strategy_temp_warm =		<4130 24 1 0 0>;
			};

			strategy_soc_85_to_90 {
				strategy_temp_little_cold =	<4430 20 1 0 0>;
				strategy_temp_cool =		<4430 20 1 0 0>;
				strategy_temp_little_cool =	<4480 20 1 0 0>;
				strategy_temp_little_cool_high =	<4480 20 1 0 0>;
				strategy_temp_normal_low =	<4480 20 1 0 0>;
				strategy_temp_normal_high =	<4480 20 1 0 0>;
				strategy_temp_warm =		<4130 24 1 0 0>;
			};
		};
	};
};

&oplus_pps_charge {
	silicon_1 {
		oplus,pps_ic = <&oplus_virtual_pps>;
		oplus,cp_ic = <&oplus_ufcs_virtual_cp>;
		oplus,dpdm_switch_ic = <&oplus_adsp_dpdm_switch>;

		// oplus,impedance_unit = <&oplus_pps_impedance_unit>;

		oplus,pps_enable_pps_status;

		oplus,target_vbus_mv = <11000>;
		oplus,curr_max_ma = <5000>;

		oplus,pps_warm_allow_vol = <4000>;
		oplus,pps_warm_allow_soc = <55>;
		oplus,pps_strategy_normal_current = <5000>;
		oplus,pps_over_high_or_low_current = <5000>;
		oplus,pps_timeout_third = <14502>;
		oplus,pps_timeout_oplus = <14502>;
		oplus,pps_ibat_over_third = <6000>;
		oplus,pps_ibat_over_oplus = <6000>;
		oplus,pps_full_cool_sw_vbat = <4570>;
		oplus,pps_full_normal_sw_vbat = <4575>;
		oplus,pps_full_normal_hw_vbat = <4585>;
		oplus,pps_full_ffc_vbat = <4495>;
		oplus,pps_full_warm_vbat = <4130>;
		oplus,pps_full_cool_sw_vbat_third = <4500>;
		oplus,pps_full_normal_sw_vbat_third= <4500>;
		oplus,pps_full_normal_hw_vbat_third = <4510>;
		oplus,pps_current_change_timeout = <100>;
		oplus,pps_r_default = <270 45 10 45 20 20 20>;
		oplus,pps_rmos_mohm = <5>;
		oplus,pps_little_cool_high_temp = <200>;
		oplus,curve_strategy_name = "pps_ufcs_curve_v2";
		oplus,pps_r_limit = <150 100 80 70 30>;
		oplus,pps_strategy_batt_high_temp = <405 420 430 395 410 425>;
		oplus,pps_strategy_high_current = <5000 4000 3000 5000 5000 4000>;
		oplus,pps_charge_strategy_soc = <0 20 35 55 75 85 95>;
		oplus,pps_charge_strategy_temp = <0 50 120 160 350 440 510>;

		pps_oplus_lcf_strategy {
			oplus,temp_type = <OPLUS_STRATEGY_USE_SHELL_TEMP>;
			oplus,temp_range = <0 50 120 160 200 350 430>;

			strategy_temp_range_curves {
				strategy_temp_range_t0 =	<370 4570 0
								 320 4560 0
								 270 4550 0
								 220 4540 0
								 170 4530 1>;
				strategy_temp_range_t1 =	<500 4570 0
								 450 4560 0
								 400 4550 0
								 350 4540 0
								 300 4530 1>;
				strategy_temp_range_t2 =	<600 4570 0
								 500 4565 0
								 400 4550 0
								 300 4540 0
								 200 4530 1>;
				strategy_temp_range_t3 =	<600 4570 0
								 500 4565 0
								 400 4550 0
								 300 4540 0
								 200 4530 1>;
				strategy_temp_range_t4 =	<1700 4570 0
								 1600 4565 0
								 1500 4550 0
								 1400 4540 0
								 1300 4530 1>;
				strategy_temp_range_t5 =	<1900 4570 0
								 1800 4565 0
								 1700 4550 0
								 1600 4540 0
								 1500 4530 1>;
			};
		};

		pps_third_lcf_strategy {
			oplus,temp_type = <OPLUS_STRATEGY_USE_SHELL_TEMP>;
			oplus,temp_range = <0 50 120 160 200 350 440>;

			strategy_temp_range_curves {
				strategy_temp_range_t0 =	<950 4500 0
								 850 4490 0
								 750 4480 0
								 650 4470 0
								 550 4460 1>;
				strategy_temp_range_t1 =	<950 4500 0
								 850 4490 0
								 750 4480 0
								 650 4470 0
								 550 4460 1>;
				strategy_temp_range_t2 =	<950 4500 0
								 850 4495 0
								 750 4480 0
								 650 4470 0
								 550 4460 1>;
				strategy_temp_range_t3 =	<950 4500 0
								 850 4495 0
								 750 4480 0
								 650 4470 0
								 550 4460 1>;
				strategy_temp_range_t4 =	<950 4500 0
								 850 4495 0
								 750 4480 0
								 650 4470 0
								 550 4460 1>;
				strategy_temp_range_t5 =	<950 4485 0
								 850 4480 0
								 750 4465 0
								 650 4455 0
								 550 4445 1>;
			};
		};

		pps_charge_third_strategy {
			oplus,temp_type = <OPLUS_STRATEGY_USE_SHELL_TEMP>;
			oplus,soc_range = <0 20 35 50 75 85 91>;
			oplus,temp_range = <0 50 120 160 200 350 440 510>;

			strategy_soc_range_min {
				strategy_temp_little_cold =	<11000 4150 1200 0 0
								11000 4500 1000 1 0>;
				strategy_temp_cool =		<11000 4150 2100 0 0
								 11000 4150 2000 0 0
								11000 4150 1500 0 0
								11000 4490 1200 0 0
								11000 4500 1000 1 0>;
				strategy_temp_little_cool =	<11000 4150 2700 0 0
								11000 4150 2500 0 0
								11000 4330 2100 0 0
								11000 4330 2000 0 0
								11000 4330 1500 0 0
								11000 4490 1200 0 0
								11000 4500 1000 1 0>;
				strategy_temp_little_cool_high =	<11000 4150 5000 0 0
								11000 4150 4500 0 0
								11000 4330 4000 0 0
								11000 4330 3500 0 0
								11000 4490 3200 0 0
								11000 4490 3000 0 0
								11000 4490 2700 0 0
								11000 4490 2500 0 0
								11000 4490 2000 0 0
								11000 4490 1500 0 0
								11000 4500 1000 1 0>;
				strategy_temp_normal_low =	<11000 4430 5000 0 0
								11000 4430 4500 0 0
								11000 4490 4000 0 0
								11000 4490 3500 0 0
								11000 4490 3000 0 0
								11000 4490 2500 0 0
								11000 4490 2000 0 0
								11000 4490 1500 0 0
								11000 4500 1000 1 0>;
				strategy_temp_normal_high =	<11000 4430 5000 0 0
								11000 4430 4500 0 0
								11000 4475 4000 0 0
								11000 4475 3500 0 0
								11000 4475 3000 0 0
								11000 4475 2500 0 0
								11000 4475 2000 0 0
								11000 4475 1500 0 0
								11000 4485 1000 1 0>;
				strategy_temp_warm =		<11000 4120 1500 0 0
								11000 4130 1000 1 0>;
			};
			strategy_soc_range_low {
				strategy_temp_little_cold =	<11000 4150 1200 0 0
								11000 4500 1000 1 0>;
				strategy_temp_cool =		<11000 4150 2100 0 0
								11000 4150 2000 0 0
								11000 4150 1500 0 0
								11000 4490 1200 0 0
								11000 4500 1000 1 0>;
				strategy_temp_little_cool =	<11000 4150 2700 0 0
								11000 4150 2500 0 0
								11000 4330 2100 0 0
								11000 4330 2000 0 0
								11000 4330 1500 0 0
								11000 4490 1200 0 0
								11000 4500 1000 1 0>;
				strategy_temp_little_cool_high =	<11000 4150 5000 0 0
								11000 4150 4500 0 0
								11000 4330 4000 0 0
								11000 4330 3500 0 0
								11000 4490 3200 0 0
								11000 4490 3000 0 0
								11000 4490 2700 0 0
								11000 4490 2500 0 0
								11000 4490 2000 0 0
								11000 4490 1500 0 0
								11000 4500 1000 1 0>;
				strategy_temp_normal_low =	<11000 4430 5000 0 0
								11000 4430 4500 0 0
								11000 4490 4000 0 0
								11000 4490 3500 0 0
								11000 4490 3000 0 0
								11000 4490 2500 0 0
								11000 4490 2000 0 0
								11000 4490 1500 0 0
								11000 4500 1000 1 0>;
				strategy_temp_normal_high =	<11000 4430 5000 0 0
								11000 4430 4500 0 0
								11000 4475 4000 0 0
								11000 4475 3500 0 0
								11000 4475 3000 0 0
								11000 4475 2500 0 0
								11000 4475 2000 0 0
								11000 4475 1500 0 0
								11000 4485 1000 1 0>;
				strategy_temp_warm =		<11000 4120 1500 0 0
								11000 4130 1000 1 0>;
			};
			strategy_soc_range_mid_low {
				strategy_temp_little_cold =	<11000 4150 1200 0 0
								11000 4500 1000 1 0>;
				strategy_temp_cool =		<11000 4150 2100 0 0
								11000 4150 2000 0 0
								11000 4150 1500 0 0
								11000 4490 1200 0 0
								11000 4500 1000 1 0>;
				strategy_temp_little_cool =	<11000 4150 2700 0 0
								11000 4150 2500 0 0
								11000 4330 2100 0 0
								11000 4330 2000 0 0
								11000 4330 1500 0 0
								11000 4490 1200 0 0
								11000 4500 1000 1 0>;
				strategy_temp_little_cool_high =	<11000 4150 5000 0 0
								11000 4150 4500 0 0
								11000 4330 4000 0 0
								11000 4330 3500 0 0
								11000 4490 3200 0 0
								11000 4490 3000 0 0
								11000 4490 2700 0 0
								11000 4490 2500 0 0
								11000 4490 2000 0 0
								11000 4490 1500 0 0
								11000 4500 1000 1 0>;
				strategy_temp_normal_low =	<11000 4430 5000 0 0
								11000 4430 4500 0 0
								11000 4490 4000 0 0
								11000 4490 3500 0 0
								11000 4490 3000 0 0
								11000 4490 2500 0 0
								11000 4490 2000 0 0
								11000 4490 1500 0 0
								11000 4500 1000 1 0>;
				strategy_temp_normal_high =	<11000 4430 5000 0 0
								11000 4430 4500 0 0
								11000 4475 4000 0 0
								11000 4475 3500 0 0
								11000 4475 3000 0 0
								11000 4475 2500 0 0
								11000 4475 2000 0 0
								11000 4475 1500 0 0
								11000 4485 1000 1 0>;
				strategy_temp_warm =		<11000 4120 1500 0 0
								11000 4130 1000 1 0>;

			};
			strategy_soc_range_mid {
				strategy_temp_little_cold =	<11000 4150 1200 0 0
								11000 4500 1000 1 0>;
				strategy_temp_cool =		<11000 4150 2000 0 0
								11000 4150 1500 0 0
								11000 4490 1200 0 0
								11000 4500 1000 1 0>;
				strategy_temp_little_cool =	<11000 4150 2700 0 0
								11000 4150 2500 0 0
								11000 4330 2100 0 0
								11000 4330 2000 0 0
								11000 4330 1500 0 0
								11000 4490 1200 0 0
								11000 4500 1000 1 0>;
				strategy_temp_little_cool_high =	<11000 4490 3000 0 0
								11000 4490 2700 0 0
								11000 4490 2500 0 0
								11000 4490 2000 0 0
								11000 4490 1500 0 0
								11000 4500 1000 1 0>;
				strategy_temp_normal_low =	<11000 4490 3500 0 0
								11000 4490 3000 0 0
								11000 4490 2500 0 0
								11000 4490 2000 0 0
								11000 4490 1500 0 0
								11000 4500 1000 1 0>;
				strategy_temp_normal_high =	<11000 4475 4000 0 0
								11000 4475 3500 0 0
								11000 4475 3000 0 0
								11000 4475 2500 0 0
								11000 4475 2000 0 0
								11000 4475 1500 0 0
								11000 4485 1000 1 0>;
				strategy_temp_warm =		<11000 4120 1500 0 0
								11000 4130 1000 1 0>;
			};
			strategy_soc_range_mid_high {
				strategy_temp_little_cold =	<11000 4500 1000 1 0>;
				strategy_temp_cool =		<11000 4150 1500 0 0
								11000 4490 1200 0 0
								11000 4500 1000 1 0>;
				strategy_temp_little_cool =	<11000 4330 2000 0 0
								11000 4330 1500 0 0
								11000 4490 1200 0 0
								11000 4500 1000 1 0>;
				strategy_temp_little_cool_high =	<11000 4490 2000 0 0
								11000 4490 1500 0 0
								11000 4500 1000 1 0>;
				strategy_temp_normal_low =	<11000 4490 2500 0 0
								11000 4490 2000 0 0
								11000 4490 1500 0 0
								11000 4500 1000 1 0>;
				strategy_temp_normal_high =	<11000 4475 2500 0 0
								11000 4475 2000 0 0
								11000 4475 1500 0 0
								11000 4485 1000 1 0>;
				strategy_temp_warm =		<11000 4120 1500 0 0
								11000 4130 1000 1 0>;
			};
			strategy_soc_range_high {
				strategy_temp_little_cold =	<11000 4500 1000 1 0>;
				strategy_temp_cool =		<11000 4500 1000 1 0>;
				strategy_temp_little_cool =	<11000 4500 1000 1 0>;
				strategy_temp_little_cool_high =	<11000 4500 1000 1 0>;
				strategy_temp_normal_low =	<11000 4500 1000 1 0>;
				strategy_temp_normal_high =	<11000 4485 1000 1 0>;
				strategy_temp_warm =		<11000 4120 1500 0 0
								11000 4130 1000 1 0>;
			};
		};

		pps_charge_oplus_strategy {
			oplus,temp_type = <OPLUS_STRATEGY_USE_SHELL_TEMP>;
			oplus,soc_range = <0 20 35 50 75 85 91>;
			oplus,temp_range = <0 50 120 160 200 350 440 510>;

			strategy_soc_range_min {
				strategy_temp_little_cold =	<11000 4150 1200 0 0
								11000 4150 1000 0 0
								11000 4570 700 1 0>;
				strategy_temp_cool =		<11000 4150 2100 0 0
								 11000 4150 2000 0 0
								11000 4150 1500 0 0
								11000 4510 1200 0 0
								11000 4510 1000 0 0
								11000 4570 700 1 0>;
				strategy_temp_little_cool =	<11000 4150 2700 0 0
								11000 4150 2500 0 0
								11000 4330 2100 0 0
								11000 4330 2000 0 0
								11000 4330 1500 0 0
								11000 4560 1200 0 0
								11000 4560 1000 0 0
								11000 4570 700 1 0>;
				strategy_temp_little_cool_high =	<11000 4150 2700 0 0
								11000 4150 2500 0 0
								11000 4330 2100 0 0
								11000 4330 2000 0 0
								11000 4330 1500 0 0
								11000 4560 1200 0 0
								11000 4560 1000 0 0
								11000 4570 700 1 0>;
				strategy_temp_normal_low =	<11000 4560 3000 0 0
								11000 4560 2500 0 0
								11000 4560 2000 0 0
								11000 4570 1800 1 0>;
				strategy_temp_normal_high =	<11000 4560 3000 0 0
								11000 4560 2500 0 0
								11000 4570 2000 1 0>;
				strategy_temp_warm =		<11000 4120 1500 0 0
								11000 4120 1000 0 0
								11000 4130 700 1 0>;
			};
			strategy_soc_range_low {
				strategy_temp_little_cold =	<11000 4150 1200 0 0
								11000 4150 1000 0 0
								11000 4570 700 1 0>;
				strategy_temp_cool =		<11000 4150 2100 0 0
								 11000 4150 2000 0 0
								11000 4150 1500 0 0
								11000 4510 1200 0 0
								11000 4510 1000 0 0
								11000 4570 700 1 0>;
				strategy_temp_little_cool =	<11000 4150 2700 0 0
								11000 4150 2500 0 0
								11000 4330 2100 0 0
								11000 4330 2000 0 0
								11000 4330 1500 0 0
								11000 4560 1200 0 0
								11000 4560 1000 0 0
								11000 4570 700 1 0>;
				strategy_temp_little_cool_high =	<11000 4150 2700 0 0
								11000 4150 2500 0 0
								11000 4330 2100 0 0
								11000 4330 2000 0 0
								11000 4330 1500 0 0
								11000 4560 1200 0 0
								11000 4560 1000 0 0
								11000 4570 700 1 0>;
				strategy_temp_normal_low =	<11000 4560 3000 0 0
								11000 4560 2500 0 0
								11000 4560 2000 0 0
								11000 4570 1800 1 0>;
				strategy_temp_normal_high =	<11000 4560 3000 0 0
								11000 4560 2500 0 0
								11000 4570 2000 1 0>;
				strategy_temp_warm =		<11000 4120 1500 0 0
								11000 4120 1000 0 0
								11000 4130 700 1 0>;
			};
			strategy_soc_range_mid_low {
				strategy_temp_little_cold =	<11000 4150 1000 0 0
								11000 4570 700 1 0>;
				strategy_temp_cool =		<11000 4150 2000 0 0
								11000 4150 1500 0 0
								11000 4510 1200 0 0
								11000 4510 1000 0 0
								11000 4570 700 1 0>;
				strategy_temp_little_cool =	<11000 4150 2700 0 0
								11000 4150 2500 0 0
								11000 4330 2100 0 0
								11000 4330 2000 0 0
								11000 4330 1500 0 0
								11000 4560 1200 0 0
								11000 4560 1000 0 0
								11000 4570 700 1 0>;
				strategy_temp_little_cool_high =	<11000 4150 2700 0 0
								11000 4150 2500 0 0
								11000 4330 2100 0 0
								11000 4330 2000 0 0
								11000 4330 1500 0 0
								11000 4560 1200 0 0
								11000 4560 1000 0 0
								11000 4570 700 1 0>;
				strategy_temp_normal_low =	<11000 4560 3000 0 0
								11000 4560 2500 0 0
								11000 4560 2000 0 0
								11000 4570 1800 1 0>;
				strategy_temp_normal_high =	<11000 4560 3000 0 0
								11000 4560 2500 0 0
								11000 4570 2000 1 0>;
				strategy_temp_warm =		<11000 4120 1500 0 0
								11000 4120 1000 0 0
								11000 4130 700 1 0>;
			};
			strategy_soc_range_mid {
				strategy_temp_little_cold =	<11000 4150 1000 0 0
								11000 4570 700 1 0>;
				strategy_temp_cool =		<11000 4150 2000 0 0
								11000 4150 1500 0 0
								11000 4510 1200 0 0
								11000 4510 1000 0 0
								11000 4570 700 1 0>;
				strategy_temp_little_cool =	<11000 4150 2700 0 0
								11000 4150 2500 0 0
								11000 4330 2100 0 0
								11000 4330 2000 0 0
								11000 4330 1500 0 0
								11000 4560 1200 0 0
								11000 4560 1000 0 0
								11000 4570 700 1 0>;
				strategy_temp_little_cool_high =	<11000 4150 2700 0 0
								11000 4150 2500 0 0
								11000 4330 2100 0 0
								11000 4330 2000 0 0
								11000 4330 1500 0 0
								11000 4560 1200 0 0
								11000 4560 1000 0 0
								11000 4570 700 1 0>;
				strategy_temp_normal_low =	<11000 4560 3000 0 0
								11000 4560 2500 0 0
								11000 4560 2000 0 0
								11000 4570 1800 1 0>;
				strategy_temp_normal_high =	<11000 4560 3000 0 0
								11000 4560 2500 0 0
								11000 4570 2000 1 0>;
				strategy_temp_warm =		<11000 4120 1500 0 0
								11000 4120 1000 0 0
								11000 4130 700 1 0>;
			};
			strategy_soc_range_mid_high {
				strategy_temp_little_cold =	<11000 4150 1000 0 0
								11000 4570 700 1 0>;
				strategy_temp_cool =		<11000 4150 2000 0 0
								11000 4150 1500 0 0
								11000 4510 1200 0 0
								11000 4510 1000 0 0
								11000 4570 700 1 0>;
				strategy_temp_little_cool =	<11000 4150 2700 0 0
								11000 4150 2500 0 0
								11000 4330 2100 0 0
								11000 4330 2000 0 0
								11000 4330 1500 0 0
								11000 4560 1200 0 0
								11000 4560 1000 0 0
								11000 4570 700 1 0>;
				strategy_temp_little_cool_high =	<11000 4150 2700 0 0
								11000 4150 2500 0 0
								11000 4330 2100 0 0
								11000 4330 2000 0 0
								11000 4330 1500 0 0
								11000 4560 1200 0 0
								11000 4560 1000 0 0
								11000 4570 700 1 0>;
				strategy_temp_normal_low =	<11000 4560 3000 0 0
								11000 4560 2500 0 0
								11000 4560 2000 0 0
								11000 4570 1800 1 0>;
				strategy_temp_normal_high =	<11000 4560 3000 0 0
								11000 4560 2500 0 0
								11000 4570 2000 1 0>;
				strategy_temp_warm =		<11000 4120 1500 0 0
								11000 4120 1000 0 0
								11000 4130 700 1 0>;
			};
			strategy_soc_range_high {
				strategy_temp_little_cold =	<11000 4150 1000 0 0
								11000 4570 700 1 0>;
				strategy_temp_cool =		<11000 4150 1500 0 0
								11000 4510 1200 0 0
								11000 4510 1000 0 0
								11000 4570 700 1 0>;
				strategy_temp_little_cool =	<11000 4330 1500 0 0
								11000 4560 1200 0 0
								11000 4560 1000 0 0
								11000 4570 700 1 0>;
				strategy_temp_little_cool_high =	<11000 4330 1500 0 0
								11000 4560 1200 0 0
								11000 4560 1000 0 0
								11000 4570 700 1 0>;
				strategy_temp_normal_low =	<11000 4560 2000 0 0
								11000 4570 1800 1 0>;
				strategy_temp_normal_high =	<11000 4570 2000 1 0>;
				strategy_temp_warm =		<11000 4120 1500 0 0
								11000 4120 1000 0 0
								11000 4130 700 1 0>;
			};
		};
	};
};

//#endif
